AUTOSAR XML (schema 00049)
package /Runnable_Lab1
  sender receiver interface SRIF_Throttle
    data CMD: type=uint32
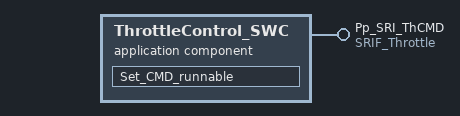
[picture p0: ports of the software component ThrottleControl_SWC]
  application sw component type ThrottleControl_SWC
    provide port Pp_SRI_ThCMD: provided-interface=SRIF_Throttle
    behavior ThController_Beh
      runnable Set_CMD_runnable: symbol=Set_CMD
        data-write-access:
          access CMD_Data: accessed-variable=Pp_SRI_ThCMD.CMD
